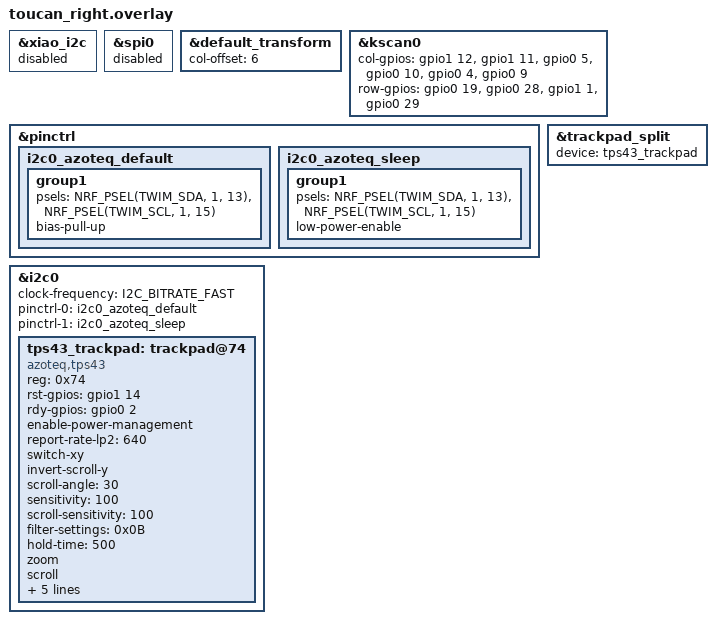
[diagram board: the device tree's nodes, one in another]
#include "toucan.dtsi"
#include <input/processors.dtsi>
#include <dt-bindings/zmk/input_transform.h>

// xiao_i2c is &i2c1 on this board; the trackpad hangs off &i2c0 instead (below).
&xiao_i2c {
    status = "disabled";
};

// SPIM0 and TWIM0 are the same nRF52840 peripheral instance -- the Cirque used SPI0 on
// these very pins, so spi0 has to stay off now that the TPS43 drives them as I2C.
&spi0 {
    status = "disabled";
};

&default_transform {
    col-offset = <6>;
};

&kscan0 {
    col-gpios
    = <&gpio1 12 GPIO_ACTIVE_HIGH>
    , <&gpio1 11 GPIO_ACTIVE_HIGH>
    , <&gpio0 5 GPIO_ACTIVE_HIGH>
    , <&gpio0 10 GPIO_ACTIVE_HIGH>
    , <&gpio0 4 GPIO_ACTIVE_HIGH>
    , <&gpio0 9 GPIO_ACTIVE_HIGH>
    ;

    row-gpios
    = <&gpio0 19 (GPIO_ACTIVE_HIGH | GPIO_PULL_DOWN)>
    , <&gpio0 28 (GPIO_ACTIVE_HIGH | GPIO_PULL_DOWN)>
    , <&gpio1 1 (GPIO_ACTIVE_HIGH | GPIO_PULL_DOWN)>
    , <&gpio0 29 (GPIO_ACTIVE_HIGH | GPIO_PULL_DOWN)>
    ;
};

// Toucan 2 upgrade kit: the converter breakout board reuses the same 7-pin cable the
// Cirque used, so the pins map straight across:
//   P1.13  SPIM_SCK          -> TWIM_SDA
//   P1.15  SPIM_MOSI         -> TWIM_SCL
//   P1.14  SPIM_MISO         -> rst-gpios
//   P0.02  data-ready-gpios  -> rdy-gpios
//   P0.03  cs-gpios          -> unused
&pinctrl {
    i2c0_azoteq_default: i2c0_azoteq_default {
        group1 {
            psels = <NRF_PSEL(TWIM_SDA, 1, 13)>,
                    <NRF_PSEL(TWIM_SCL, 1, 15)>;
            bias-pull-up;
        };
    };

    i2c0_azoteq_sleep: i2c0_azoteq_sleep {
        group1 {
            psels = <NRF_PSEL(TWIM_SDA, 1, 13)>,
                    <NRF_PSEL(TWIM_SCL, 1, 15)>;
            low-power-enable;
        };
    };
};

&i2c0 {
    status = "okay";
    clock-frequency = <I2C_BITRATE_FAST>;
    pinctrl-0 = <&i2c0_azoteq_default>;
    pinctrl-1 = <&i2c0_azoteq_sleep>;
    pinctrl-names = "default", "sleep";

    tps43_trackpad: trackpad@74 {
        compatible = "azoteq,tps43";
        reg = <0x74>;
        status = "okay";

        rst-gpios = <&gpio1 14 GPIO_ACTIVE_HIGH>;
        rdy-gpios = <&gpio0 2 GPIO_ACTIVE_HIGH>;

        // Power management lives on the sensor now (the Cirque used ZMK-side hooks).
        enable-power-management;
        // idle-sleep gives maximal savings but the pad stops working once ZMK goes idle
        // (~30s without a keypress), which is not worth it.
        // idle-sleep;
        // 640ms LP2 report rate draws ~55uA instead of the default 160ms / ~174uA.
        report-rate-lp2 = <640>;

        // Orientation and feel -- these come from the kit's trackpad mount, which is the
        // same part upstream toucan2 ships, so they are copied verbatim.
        switch-xy;
        invert-scroll-y;
        scroll-angle = <30>;      // the ~47deg default is too wide for this pad
        sensitivity = <100>;
        scroll-sensitivity = <100>;
        filter-settings = <0x0B>; // IIR + MAV + ALP, dynamic IIR
        hold-time = <500>;

        // Gestures. Note `swipes` (deliberately off) is the SINGLE-finger swipe gesture --
        // enabling it would fire the desktop-switch shortcuts during ordinary cursor
        // movement. `three-finger-swipe` is an independent property for the 3-finger case
        // (see tps43_handle_swipe in tps43.c). It is derived from raw deltas on every
        // report rather than a one-shot hardware gesture, hence the throttle.
        zoom;
        scroll;
        single-tap;
        two-finger-tap;
        press-and-hold;
        three-finger-swipe;
        three-finger-swipe-throttle-ms = <1200>;
    };
};

&trackpad_split {
    device = <&tps43_trackpad>;
};
